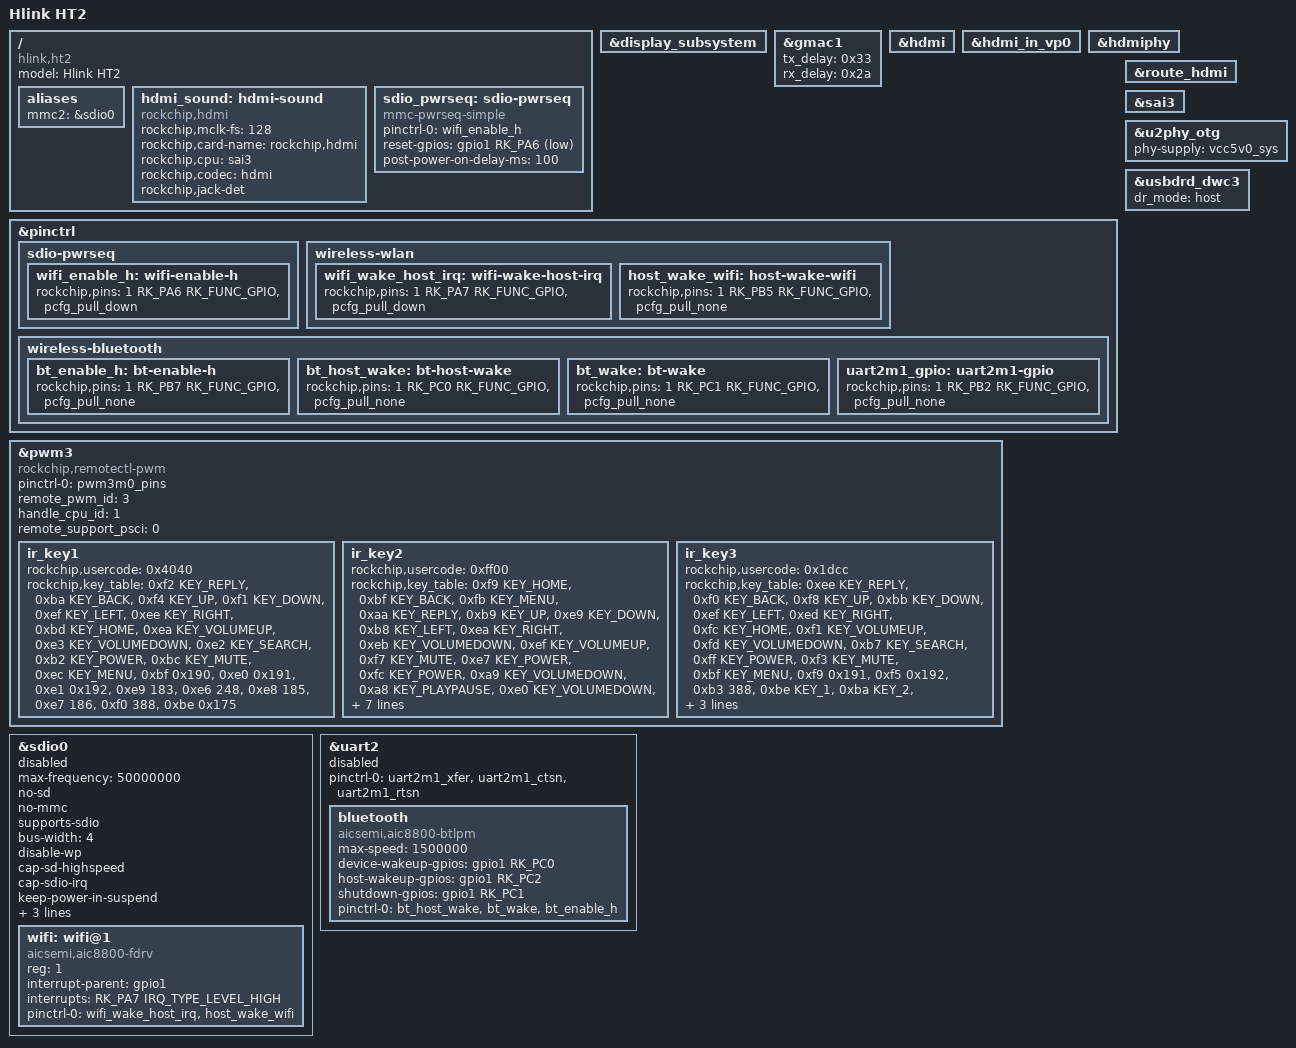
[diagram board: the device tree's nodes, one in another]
// SPDX-License-Identifier: (GPL-2.0+ OR MIT)
/*
 * Copyright (c) 2022 Rockchip Electronics Co., Ltd.
 * Author: flippy (flippy@sina.com)
 *
 */

#include "rk3528-hlink.dtsi"

/ {
	model = "Hlink HT2";
	compatible = "hlink,ht2", "rockchip,rk3528";

	aliases {
		mmc2 = &sdio0;
	};

	hdmi_sound: hdmi-sound {
		compatible = "rockchip,hdmi";
		rockchip,mclk-fs = <128>;
		rockchip,card-name = "rockchip,hdmi";
		rockchip,cpu = <&sai3>;
		rockchip,codec = <&hdmi>;
		rockchip,jack-det;
	};

	sdio_pwrseq: sdio-pwrseq {
		status = "okay";
		compatible = "mmc-pwrseq-simple";
		pinctrl-names = "default";
		pinctrl-0 = <&wifi_enable_h>;
		reset-gpios = <&gpio1 RK_PA6 GPIO_ACTIVE_LOW>;
		post-power-on-delay-ms = <100>;
	};
};

&display_subsystem {
	status = "okay";
};

&gmac1 {
	tx_delay = <0x33>;
	rx_delay = <0x2a>;
};

&hdmi {
	status = "okay";
};

&hdmi_in_vp0 {
	status = "okay";
};

&hdmiphy {
	status = "okay";
};

&pinctrl {
	sdio-pwrseq {
		wifi_enable_h: wifi-enable-h {
			rockchip,pins = <1 RK_PA6 RK_FUNC_GPIO &pcfg_pull_down>;
		};
	};

	wireless-wlan {
		wifi_wake_host_irq: wifi-wake-host-irq {
			rockchip,pins = <1 RK_PA7 RK_FUNC_GPIO &pcfg_pull_down>;
		};

		host_wake_wifi: host-wake-wifi {
			rockchip,pins = <1 RK_PB5 RK_FUNC_GPIO &pcfg_pull_none>;
		};
	};

	wireless-bluetooth {
		bt_enable_h: bt-enable-h {
			rockchip,pins = <1 RK_PB7 RK_FUNC_GPIO &pcfg_pull_none>;
		};

		bt_host_wake: bt-host-wake {
			rockchip,pins = <1 RK_PC0 RK_FUNC_GPIO &pcfg_pull_none>;
		};

		bt_wake: bt-wake {
			rockchip,pins = <1 RK_PC1 RK_FUNC_GPIO &pcfg_pull_none>;
		};

		uart2m1_gpio: uart2m1-gpio {
			rockchip,pins = <1 RK_PB2 RK_FUNC_GPIO &pcfg_pull_none>;
		};
	};
};

&pwm3 {
	compatible = "rockchip,remotectl-pwm";
	pinctrl-names = "default";
	pinctrl-0 = <&pwm3m0_pins>;
	remote_pwm_id = <3>;
	handle_cpu_id = <1>;
	remote_support_psci = <0>;
	status = "okay";

	ir_key1 {
		rockchip,usercode = <0x4040>;
		rockchip,key_table =
			<0xf2	KEY_REPLY>,
			<0xba	KEY_BACK>,
			<0xf4	KEY_UP>,
			<0xf1	KEY_DOWN>,
			<0xef	KEY_LEFT>,
			<0xee	KEY_RIGHT>,
			<0xbd	KEY_HOME>,
			<0xea	KEY_VOLUMEUP>,
			<0xe3	KEY_VOLUMEDOWN>,
			<0xe2	KEY_SEARCH>,
			<0xb2	KEY_POWER>,
			<0xbc	KEY_MUTE>,
			<0xec	KEY_MENU>,
			<0xbf	0x190>,
			<0xe0	0x191>,
			<0xe1	0x192>,
			<0xe9	183>,
			<0xe6	248>,
			<0xe8	185>,
			<0xe7	186>,
			<0xf0	388>,
			<0xbe	0x175>;
	};

	ir_key2 {
		rockchip,usercode = <0xff00>;
		rockchip,key_table =
			<0xf9	KEY_HOME>,
			<0xbf	KEY_BACK>,
			<0xfb	KEY_MENU>,
			<0xaa	KEY_REPLY>,
			<0xb9	KEY_UP>,
			<0xe9	KEY_DOWN>,
			<0xb8	KEY_LEFT>,
			<0xea	KEY_RIGHT>,
			<0xeb	KEY_VOLUMEDOWN>,
			<0xef	KEY_VOLUMEUP>,
			<0xf7	KEY_MUTE>,
			<0xe7	KEY_POWER>,
			<0xfc	KEY_POWER>,
			<0xa9	KEY_VOLUMEDOWN>,
			<0xa8	KEY_PLAYPAUSE>,
			<0xe0	KEY_VOLUMEDOWN>,
			<0xa5	KEY_VOLUMEDOWN>,
			<0xab	183>,
			<0xb7	388>,
			<0xe8	388>,
			<0xf8	184>,
			<0xaf	185>,
			<0xed	KEY_VOLUMEDOWN>,
			<0xee	186>,
			<0xb3	KEY_VOLUMEDOWN>,
			<0xf1	KEY_VOLUMEDOWN>,
			<0xf2	KEY_VOLUMEDOWN>,
			<0xf3	KEY_SEARCH>,
			<0xb4	KEY_VOLUMEDOWN>,
			<0xa4	KEY_SETUP>,
			<0xbe	KEY_SEARCH>;
	};

	ir_key3 {
		rockchip,usercode = <0x1dcc>;
		rockchip,key_table =
			<0xee	KEY_REPLY>,
			<0xf0	KEY_BACK>,
			<0xf8	KEY_UP>,
			<0xbb	KEY_DOWN>,
			<0xef	KEY_LEFT>,
			<0xed	KEY_RIGHT>,
			<0xfc	KEY_HOME>,
			<0xf1	KEY_VOLUMEUP>,
			<0xfd	KEY_VOLUMEDOWN>,
			<0xb7	KEY_SEARCH>,
			<0xff	KEY_POWER>,
			<0xf3	KEY_MUTE>,
			<0xbf	KEY_MENU>,
			<0xf9	0x191>,
			<0xf5	0x192>,
			<0xb3	388>,
			<0xbe	KEY_1>,
			<0xba	KEY_2>,
			<0xb2	KEY_3>,
			<0xbd	KEY_4>,
			<0xf9	KEY_5>,
			<0xb1	KEY_6>,
			<0xfc	KEY_7>,
			<0xf8	KEY_8>,
			<0xb0	KEY_9>,
			<0xb6	KEY_0>,
			<0xb5	KEY_BACKSPACE>;
	};
};

&route_hdmi {
	status = "okay";
};

&sai3 {
	status = "okay";
};

&sdio0 {
	#address-cells = <1>;
	#size-cells = <0>;
	max-frequency = <50000000>;
	no-sd;
	no-mmc;
	supports-sdio;
	bus-width = <4>;
	disable-wp;
	cap-sd-highspeed;
	cap-sdio-irq;
	keep-power-in-suspend;
	non-removable;
	mmc-pwrseq = <&sdio_pwrseq>;
	pinctrl-names = "default";
	pinctrl-0 = <&sdio0_bus4 &sdio0_cmd &sdio0_clk>;
	status = "disabled";

	wifi: wifi@1 {
		compatible = "aicsemi,aic8800-fdrv";
		reg = <1>;
		interrupt-parent = <&gpio1>;
		interrupts = <RK_PA7 IRQ_TYPE_LEVEL_HIGH>;
		interrupt-names = "host-wake";
		pinctrl-names = "default";
		pinctrl-0 = <&wifi_wake_host_irq &host_wake_wifi>;
	};
};

&uart2 {
	status = "disabled";
	pinctrl-names = "default";
	//pinctrl-0 = <&uart2m1_xfer &uart2m1_ctsn &uart2m1_gpio>;
	pinctrl-0 = <&uart2m1_xfer &uart2m1_ctsn &uart2m1_rtsn>;

	bluetooth: bluetooth {
		compatible = "aicsemi,aic8800-btlpm";
		max-speed = <1500000>;
		device-wakeup-gpios = <&gpio1 RK_PC0 GPIO_ACTIVE_HIGH>;
		host-wakeup-gpios = <&gpio1 RK_PC2 GPIO_ACTIVE_HIGH>;
		shutdown-gpios = <&gpio1 RK_PC1 GPIO_ACTIVE_HIGH>;
		pinctrl-names = "default";
		pinctrl-0 = <&bt_host_wake &bt_wake &bt_enable_h>;
	};
};

&u2phy_otg {
	phy-supply = <&vcc5v0_sys>;
	status = "okay";
};

&usbdrd_dwc3 {
	status = "okay";
	dr_mode = "host";
};
